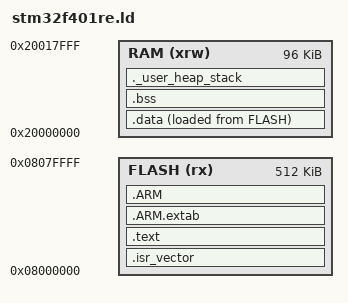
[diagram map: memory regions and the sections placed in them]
/*
 * STM32F401RE (Nucleo-F401RE) linker script
 *   Flash : 512 KB @ 0x08000000
 *   SRAM  :  96 KB @ 0x20000000
 */

ENTRY(Reset_Handler)

_estack = ORIGIN(RAM) + LENGTH(RAM);   /* top of SRAM = initial SP */

_Min_Heap_Size  = 0x200;   /* 512 B  */
_Min_Stack_Size = 0x800;   /* 2 KB   */

MEMORY
{
  FLASH (rx)  : ORIGIN = 0x08000000, LENGTH = 512K
  RAM   (xrw) : ORIGIN = 0x20000000, LENGTH = 96K
}

SECTIONS
{
  /* Interrupt vector table must live at address 0 of the (remapped) flash */
  .isr_vector :
  {
    . = ALIGN(4);
    KEEP(*(.isr_vector))
    . = ALIGN(4);
  } >FLASH

  .text :
  {
    . = ALIGN(4);
    *(.text)
    *(.text*)
    *(.rodata)
    *(.rodata*)
    . = ALIGN(4);
    _etext = .;
  } >FLASH

  .ARM.extab : { *(.ARM.extab* .gnu.linkonce.armextab.*) } >FLASH
  .ARM : {
    __exidx_start = .;
    *(.ARM.exidx*)
    __exidx_end = .;
  } >FLASH

  _sidata = LOADADDR(.data);

  /* Initialised data: lives in SRAM, image stored in flash */
  .data :
  {
    . = ALIGN(4);
    _sdata = .;
    *(.data)
    *(.data*)
    . = ALIGN(4);
    _edata = .;
  } >RAM AT> FLASH

  /* Zero-initialised data */
  .bss :
  {
    . = ALIGN(4);
    _sbss = .;
    __bss_start__ = _sbss;
    *(.bss)
    *(.bss*)
    *(COMMON)
    . = ALIGN(4);
    _ebss = .;
    __bss_end__ = _ebss;
  } >RAM

  /* Reserve heap + stack so a stack overflow cannot silently corrupt .bss */
  ._user_heap_stack :
  {
    . = ALIGN(8);
    _end = .;
    . = . + _Min_Heap_Size;
    . = . + _Min_Stack_Size;
    . = ALIGN(8);
  } >RAM

  /DISCARD/ : { *(.note.GNU-stack) *(.gnu_debuglink) }
}
